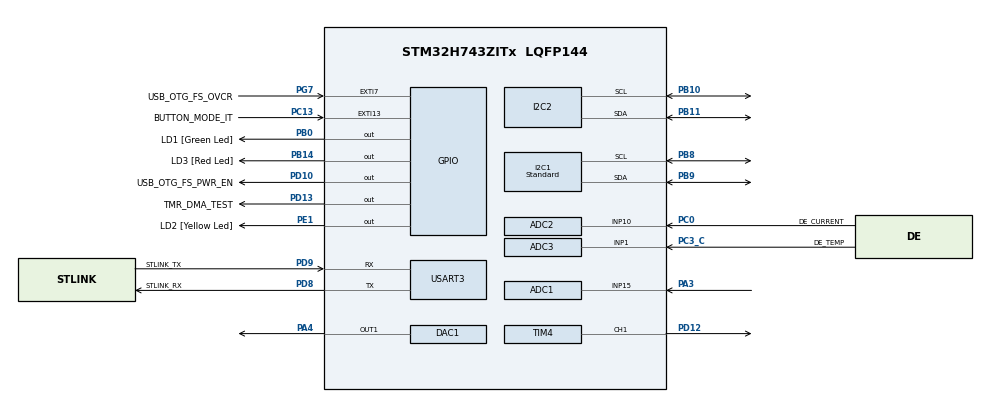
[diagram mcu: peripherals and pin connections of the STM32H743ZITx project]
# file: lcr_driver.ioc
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ADC1.Channel-0\#ChannelRegularConversion=ADC_CHANNEL_15
ADC1.ClockPrescaler=ADC_CLOCK_ASYNC_DIV1
ADC1.ContinuousConvMode=DISABLE
ADC1.ConversionDataManagement=ADC_CONVERSIONDATA_DMA_ONESHOT
ADC1.ExternalTrigConv=ADC_EXTERNALTRIG_T4_TRGO
ADC1.NbrOfConversion=1
ADC1.NbrOfConversionFlag=1
ADC1.OversamplingMode=ENABLE
ADC1.OversamplingStopReset=ADC_REGOVERSAMPLING_RESUMED_MODE
ADC1.Ratio=2
ADC1.RightBitShift=ADC_RIGHTBITSHIFT_1
ADC1.TriggeredMode=ADC_TRIGGEREDMODE_MULTI_TRIGGER
ADC1.master=1
ADC2.Channel-0\#ChannelRegularConversion=ADC_CHANNEL_10
ADC2.ContinuousConvMode=DISABLE
ADC2.ConversionDataManagement=ADC_CONVERSIONDATA_DMA_ONESHOT
ADC2.DiscontinuousConvMode=DISABLE
ADC2.ExternalTrigConv=ADC_EXTERNALTRIG_T4_TRGO
ADC2.NbrOfConversionFlag=1
ADC2.OffsetNumber-0\#ChannelRegularConversion=ADC_OFFSET_NONE
ADC2.OffsetSignedSaturation-0\#ChannelRegularConversion=DISABLE
ADC2.OversamplingMode=ENABLE
ADC2.OversamplingStopReset=ADC_REGOVERSAMPLING_RESUMED_MODE
ADC2.Rank-0\#ChannelRegularConversion=1
ADC2.Ratio=2
ADC2.Resolution=ADC_RESOLUTION_16B
ADC2.RightBitShift=ADC_RIGHTBITSHIFT_1
ADC2.SamplingTime-0\#ChannelRegularConversion=ADC_SAMPLETIME_1CYCLE_5
ADC2.TriggeredMode=ADC_TRIGGEREDMODE_MULTI_TRIGGER
ADC3.Channel-0\#ChannelRegularConversion=ADC_CHANNEL_1
ADC3.ContinuousConvMode=DISABLE
ADC3.ConversionDataManagement=ADC_CONVERSIONDATA_DMA_CIRCULAR
ADC3.ExternalTrigConv=ADC_EXTERNALTRIG_T4_TRGO
ADC3.NbrOfConversionFlag=1
ADC3.OffsetNumber-0\#ChannelRegularConversion=ADC_OFFSET_NONE
ADC3.OffsetSignedSaturation-0\#ChannelRegularConversion=DISABLE
ADC3.Rank-0\#ChannelRegularConversion=1
ADC3.SamplingTime-0\#ChannelRegularConversion=ADC_SAMPLETIME_1CYCLE_5
DAC1.DAC_Channel-DAC_OUT1=DAC_CHANNEL_1
DAC1.DAC_Trigger-DAC_OUT1=DAC_TRIGGER_T6_TRGO
Dma.ADC1.3.Direction=DMA_PERIPH_TO_MEMORY
Dma.ADC1.3.EventEnable=DISABLE
Dma.ADC1.3.FIFOMode=DMA_FIFOMODE_DISABLE
Dma.ADC1.3.Instance=DMA2_Stream0
Dma.ADC1.3.MemDataAlignment=DMA_MDATAALIGN_HALFWORD
Dma.ADC1.3.MemInc=DMA_MINC_ENABLE
Dma.ADC1.3.Mode=DMA_NORMAL
Dma.ADC1.3.PeriphDataAlignment=DMA_PDATAALIGN_HALFWORD
Dma.ADC1.3.PeriphInc=DMA_PINC_DISABLE
Dma.ADC1.3.Polarity=HAL_DMAMUX_REQ_GEN_RISING
Dma.ADC1.3.Priority=DMA_PRIORITY_LOW
Dma.ADC1.3.RequestNumber=1
Dma.ADC1.3.SignalID=NONE
Dma.ADC1.3.SyncEnable=DISABLE
Dma.ADC1.3.SyncPolarity=HAL_DMAMUX_SYNC_NO_EVENT
Dma.ADC1.3.SyncRequestNumber=1
Dma.ADC1.3.SyncSignalID=NONE
Dma.ADC2.1.Direction=DMA_PERIPH_TO_MEMORY
Dma.ADC2.1.EventEnable=DISABLE
Dma.ADC2.1.FIFOMode=DMA_FIFOMODE_DISABLE
Dma.ADC2.1.Instance=DMA2_Stream1
Dma.ADC2.1.MemDataAlignment=DMA_MDATAALIGN_HALFWORD
Dma.ADC2.1.MemInc=DMA_MINC_ENABLE
Dma.ADC2.1.Mode=DMA_NORMAL
Dma.ADC2.1.PeriphDataAlignment=DMA_PDATAALIGN_HALFWORD
Dma.ADC2.1.PeriphInc=DMA_PINC_DISABLE
Dma.ADC2.1.Polarity=HAL_DMAMUX_REQ_GEN_RISING
Dma.ADC2.1.Priority=DMA_PRIORITY_LOW
Dma.ADC2.1.RequestNumber=1
Dma.ADC2.1.SignalID=NONE
Dma.ADC2.1.SyncEnable=DISABLE
Dma.ADC2.1.SyncPolarity=HAL_DMAMUX_SYNC_NO_EVENT
Dma.ADC2.1.SyncRequestNumber=1
Dma.ADC2.1.SyncSignalID=NONE
Dma.ADC3.2.Direction=DMA_PERIPH_TO_MEMORY
Dma.ADC3.2.EventEnable=DISABLE
Dma.ADC3.2.FIFOMode=DMA_FIFOMODE_DISABLE
Dma.ADC3.2.Instance=DMA2_Stream2
Dma.ADC3.2.MemDataAlignment=DMA_MDATAALIGN_HALFWORD
Dma.ADC3.2.MemInc=DMA_MINC_ENABLE
Dma.ADC3.2.Mode=DMA_CIRCULAR
Dma.ADC3.2.PeriphDataAlignment=DMA_PDATAALIGN_HALFWORD
Dma.ADC3.2.PeriphInc=DMA_PINC_DISABLE
Dma.ADC3.2.Polarity=HAL_DMAMUX_REQ_GEN_RISING
Dma.ADC3.2.Priority=DMA_PRIORITY_LOW
Dma.ADC3.2.RequestNumber=1
Dma.ADC3.2.SignalID=NONE
Dma.ADC3.2.SyncEnable=DISABLE
Dma.ADC3.2.SyncPolarity=HAL_DMAMUX_SYNC_NO_EVENT
Dma.ADC3.2.SyncRequestNumber=1
Dma.ADC3.2.SyncSignalID=NONE
Dma.DAC1_CH1.0.Direction=DMA_MEMORY_TO_PERIPH
Dma.DAC1_CH1.0.EventEnable=DISABLE
Dma.DAC1_CH1.0.FIFOMode=DMA_FIFOMODE_DISABLE
Dma.DAC1_CH1.0.Instance=DMA1_Stream0
Dma.DAC1_CH1.0.MemDataAlignment=DMA_MDATAALIGN_HALFWORD
Dma.DAC1_CH1.0.MemInc=DMA_MINC_ENABLE
Dma.DAC1_CH1.0.Mode=DMA_CIRCULAR
Dma.DAC1_CH1.0.PeriphDataAlignment=DMA_PDATAALIGN_HALFWORD
Dma.DAC1_CH1.0.PeriphInc=DMA_PINC_DISABLE
Dma.DAC1_CH1.0.Polarity=HAL_DMAMUX_REQ_GEN_RISING
Dma.DAC1_CH1.0.Priority=DMA_PRIORITY_LOW
Dma.DAC1_CH1.0.RequestNumber=1
Dma.DAC1_CH1.0.SignalID=NONE
Dma.DAC1_CH1.0.SyncEnable=DISABLE
Dma.DAC1_CH1.0.SyncPolarity=HAL_DMAMUX_SYNC_NO_EVENT
Dma.DAC1_CH1.0.SyncRequestNumber=1
Dma.DAC1_CH1.0.SyncSignalID=NONE
Dma.Request0=DAC1_CH1
Dma.Request1=ADC2
Dma.Request2=ADC3
Dma.Request3=ADC1
FREERTOS.Tasks01=defaultTask,9,128,StartDefaultTask,Default,NULL,Dynamic,NULL,NULL;oledDisplay,17,512,Display_StartThread,As external,&hi2c1,Dynamic,NULL,NULL;analogOut,41,128,AnalogOut_StartThread,As external,&analog_out_params,Dynamic,NULL,NULL;mainThread,25,128,MainThread_StartThread,As external,&hi2c2,Dynamic,NULL,NULL;analogIn,42,2048,AnalogIn_StartThread,As external,&analog_in_params,Dynamic,NULL,NULL
FREERTOS.configUSE_NEWLIB_REENTRANT=1
I2C1.CustomTiming=Disabled
I2C1.I2C_Speed_Mode=I2C_Standard
I2C1.Timing=0x307075B1
I2C2.OwnAddress=0x60
I2C2.Timing=0x307075B1
Mcu.Family=STM32H7
Mcu.Name=STM32H743ZITx
Mcu.Package=LQFP144
NVIC.DMA1_Stream0_IRQn=true\:5\:0\:false\:false\:true\:true\:false\:true
NVIC.DMA2_Stream0_IRQn=true\:5\:0\:false\:false\:true\:false\:false\:true
NVIC.DMA2_Stream1_IRQn=true\:5\:0\:false\:false\:true\:true\:false\:true
NVIC.DMA2_Stream2_IRQn=true\:5\:0\:false\:false\:true\:true\:false\:true
NVIC.EXTI15_10_IRQn=true\:5\:0\:false\:false\:true\:true\:true\:true
NVIC.FLASH_IRQn=true\:5\:0\:false\:false\:true\:true\:true\:true
NVIC.I2C2_ER_IRQn=true\:5\:0\:false\:false\:true\:true\:true\:true
NVIC.I2C2_EV_IRQn=true\:5\:0\:false\:false\:true\:true\:true\:true
NVIC.PriorityGroup=NVIC_PRIORITYGROUP_4
NVIC.TIM7_IRQn=true\:15\:0\:false\:false\:true\:false\:false\:true
NVIC.TimeBase=TIM7_IRQn
NVIC.TimeBaseIP=TIM7
PA3.GPIO_Mode=GPIO_MODE_ANALOG
PA3.GPIO_PuPd=GPIO_NOPULL
PA3.Signal=ADCx_INP15
PA4.Signal=COMP_DAC11_group
PB0.GPIO_Label=LD1 [Green Led]
PB0.Signal=GPIO_Output
PB10.Mode=I2C
PB10.Signal=I2C2_SCL
PB11.Mode=I2C
PB11.Signal=I2C2_SDA
PB14.GPIO_Label=LD3 [Red Led]
PB14.Signal=GPIO_Output
PB8.Mode=I2C
PB8.Signal=I2C1_SCL
PB9.Mode=I2C
PB9.Signal=I2C1_SDA
PC0.GPIO_Label=DE_CURRENT
PC0.Signal=ADCx_INP10
PC13.GPIO_Label=BUTTON_MODE_IT
PC13.Signal=GPXTI13
PC14-OSC32_IN\ (OSC32_IN).Mode=LSE-External-Oscillator
PC14-OSC32_IN\ (OSC32_IN).Signal=RCC_OSC32_IN
PC15-OSC32_OUT\ (OSC32_OUT).Mode=LSE-External-Oscillator
PC15-OSC32_OUT\ (OSC32_OUT).Signal=RCC_OSC32_OUT
PC3_C.GPIO_Label=DE_TEMP
PC3_C.Mode=IN1-Single-Ended
PC3_C.Signal=ADC3_INP1
PD10.GPIO_Label=USB_OTG_FS_PWR_EN
PD10.Signal=GPIO_Output
PD12.Signal=S_TIM4_CH1
PD13.GPIO_Label=TMR_DMA_TEST
PD13.Signal=GPIO_Output
PD8.GPIO_Label=STLINK_RX
PD8.Mode=Asynchronous
PD8.Signal=USART3_TX
PD9.GPIO_Label=STLINK_TX
PD9.Mode=Asynchronous
PD9.Signal=USART3_RX
PE1.GPIO_Label=LD2 [Yellow Led]
PE1.Signal=GPIO_Output
PG7.GPIO_Label=USB_OTG_FS_OVCR
PG7.Signal=GPXTI7
PH0-OSC_IN\ (PH0).Mode=HSE-External-Clock-Source
PH0-OSC_IN\ (PH0).Signal=RCC_OSC_IN
ProjectManager.HeapSize=0x200
ProjectManager.StackSize=0x400
ProjectManager.TargetToolchain=STM32CubeIDE
RCC.ADCFreq_Value=75000000
RCC.APB1Freq_Value=120000000
RCC.APB2Freq_Value=120000000
RCC.APB3Freq_Value=120000000
RCC.APB4Freq_Value=120000000
RCC.CortexFreq_Value=480000000
RCC.D1PPRE=RCC_APB3_DIV2
RCC.D2PPRE1=RCC_APB1_DIV2
RCC.D2PPRE2=RCC_APB2_DIV2
RCC.D3PPRE=RCC_APB4_DIV2
RCC.DIVM1=4
RCC.DIVM2=4
RCC.DIVM3=4
RCC.DIVN1=60
RCC.DIVN2=9
RCC.DIVN3=10
RCC.HCLKFreq_Value=240000000
RCC.HPRE=RCC_HCLK_DIV2
RCC.PLL2FRACN=3072
RCC.PLL3FRACN=0
RCC.PLLFRACN=0
RCC.PWR_Regulator_Voltage_Scale=PWR_REGULATOR_VOLTAGE_SCALE0
RCC.SYSCLKFreq_VALUE=480000000
RCC.SYSCLKSource=RCC_SYSCLKSOURCE_PLLCLK
RCC.USBFreq_Value=480000000
SH.ADCx_INP10.0=ADC2_INP10,IN10-Single-Ended
SH.ADCx_INP15.0=ADC1_INP15,IN15-Single-Ended
SH.COMP_DAC11_group.0=DAC1_OUT1,DAC_OUT1
SH.S_TIM4_CH1.0=TIM4_CH1,Output Compare1 CH1
TIM4.AutoReloadPreload=TIM_AUTORELOAD_PRELOAD_ENABLE
TIM4.Channel-Output\ Compare1\ CH1=TIM_CHANNEL_1
TIM4.OCMode_1=TIM_OCMODE_TOGGLE
TIM4.Period=94-1
TIM4.TIM_MasterOutputTrigger=TIM_TRGO_UPDATE
TIM6.Period=240-1
TIM6.Prescaler=0
TIM6.TIM_MasterOutputTrigger=TIM_TRGO_UPDATE
USART3.VirtualMode-Asynchronous=VM_ASYNC
VP_FREERTOS_VS_CMSIS_V2.Mode=CMSIS_V2
VP_SYS_VS_tim7.Mode=TIM7
VP_TIM4_VS_ClockSourceINT.Mode=Internal
VP_TIM6_VS_ClockSourceINT.Mode=Enable_Timer
board=NUCLEO-H743ZI2

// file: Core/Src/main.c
/* USER CODE BEGIN Header */
/**
 ******************************************************************************
 * @file           : main.c
 * @brief          : Main program body
 ******************************************************************************
 * @attention
 *
 * <h2><center>&copy; Copyright (c) 2021 STMicroelectronics.
 * All rights reserved.</center></h2>
 *
 * This software component is licensed by ST under BSD 3-Clause license,
 * the "License"; You may not use this file except in compliance with the
 * License. You may obtain a copy of the License at:
 *                        opensource.org/licenses/BSD-3-Clause
 *
 ******************************************************************************
 */
/* USER CODE END Header */
#include "main.h"
#include "cmsis_os.h"

ADC_HandleTypeDef hadc1;
ADC_HandleTypeDef hadc2;
ADC_HandleTypeDef hadc3;
DMA_HandleTypeDef hdma_adc1;
DMA_HandleTypeDef hdma_adc2;
DMA_HandleTypeDef hdma_adc3;

DAC_HandleTypeDef hdac1;
DMA_HandleTypeDef hdma_dac1_ch1;

I2C_HandleTypeDef hi2c1;
I2C_HandleTypeDef hi2c2;

TIM_HandleTypeDef htim4;
TIM_HandleTypeDef htim6;

UART_HandleTypeDef huart3;

/* Definitions for defaultTask */
osThreadId_t defaultTaskHandle;
const osThreadAttr_t defaultTask_attributes = {
  .name = "defaultTask",
  .stack_size = 128 * 4,
  .priority = (osPriority_t) osPriorityLow1,
};
/* Definitions for oledDisplay */
osThreadId_t oledDisplayHandle;
const osThreadAttr_t oledDisplay_attributes = {
  .name = "oledDisplay",
  .stack_size = 512 * 4,
  .priority = (osPriority_t) osPriorityBelowNormal1,
};
/* Definitions for analogOut */
osThreadId_t analogOutHandle;
const osThreadAttr_t analogOut_attributes = {
  .name = "analogOut",
  .stack_size = 128 * 4,
  .priority = (osPriority_t) osPriorityHigh1,
};
/* Definitions for mainThread */
osThreadId_t mainThreadHandle;
const osThreadAttr_t mainThread_attributes = {
  .name = "mainThread",
  .stack_size = 128 * 4,
  .priority = (osPriority_t) osPriorityNormal1,
};
/* Definitions for analogIn */
osThreadId_t analogInHandle;
const osThreadAttr_t analogIn_attributes = {
  .name = "analogIn",
  .stack_size = 2048 * 4,
  .priority = (osPriority_t) osPriorityHigh2,
};
/* USER CODE BEGIN PV */

// these threads need multiple parameters, therefore we pass a reference to a struct
AnalogOut_Parameter_t analog_out_params = {&htim6, &hdac1, &hi2c1};
AnalogIn_Parameter_t analog_in_params = {&hadc1, &hadc2, &hadc3, &htim4};

/* USER CODE END PV */

void SystemClock_Config(void);
void PeriphCommonClock_Config(void);
static void MX_GPIO_Init(void);
static void MX_DMA_Init(void);
static void MX_TIM4_Init(void);
static void MX_TIM6_Init(void);
static void MX_USART3_UART_Init(void);
static void MX_DAC1_Init(void);
static void MX_ADC1_Init(void);
static void MX_ADC2_Init(void);
static void MX_ADC3_Init(void);
static void MX_I2C1_Init(void);
static void MX_I2C2_Init(void);
void StartDefaultTask(void *argument);
extern void Display_StartThread(void *argument);
extern void AnalogOut_StartThread(void *argument);
extern void MainThread_StartThread(void *argument);
extern void AnalogIn_StartThread(void *argument);

int main(void)
{

  /* MCU Configuration--------------------------------------------------------*/

  /* Reset of all peripherals, Initializes the Flash interface and the Systick. */
  HAL_Init();

  /* Configure the system clock */
  SystemClock_Config();

/* Configure the peripherals common clocks */
  PeriphCommonClock_Config();

  /* Initialize all configured peripherals */
  MX_GPIO_Init();
  MX_DMA_Init();
  MX_TIM4_Init();
  MX_TIM6_Init();
  MX_USART3_UART_Init();
  MX_DAC1_Init();
  MX_ADC1_Init();
  MX_ADC2_Init();
  MX_ADC3_Init();
  MX_I2C1_Init();
  MX_I2C2_Init();

  /* Init scheduler */
  osKernelInitialize();

  /* Create the thread(s) */
  /* creation of defaultTask */
  defaultTaskHandle = osThreadNew(StartDefaultTask, NULL, &defaultTask_attributes);

  /* creation of oledDisplay */
  oledDisplayHandle = osThreadNew(Display_StartThread, (void*) &hi2c1, &oledDisplay_attributes);

  /* creation of analogOut */
  analogOutHandle = osThreadNew(AnalogOut_StartThread, (void*) &analog_out_params, &analogOut_attributes);

  /* creation of mainThread */
  mainThreadHandle = osThreadNew(MainThread_StartThread, (void*) &hi2c2, &mainThread_attributes);

  /* creation of analogIn */
  analogInHandle = osThreadNew(AnalogIn_StartThread, (void*) &analog_in_params, &analogIn_attributes);

  /* Start scheduler */
  osKernelStart();

  /* We should never get here as control is now taken by the scheduler */
  /* Infinite loop */
  while (1) {

  }
}

void SystemClock_Config(void)
{
  RCC_OscInitTypeDef RCC_OscInitStruct = {0};
  RCC_ClkInitTypeDef RCC_ClkInitStruct = {0};

  /** Supply configuration update enable
  */
  HAL_PWREx_ConfigSupply(PWR_LDO_SUPPLY);
  /** Configure the main internal regulator output voltage
  */
  __HAL_PWR_VOLTAGESCALING_CONFIG(PWR_REGULATOR_VOLTAGE_SCALE0);

  while(!__HAL_PWR_GET_FLAG(PWR_FLAG_VOSRDY)) {}
  /** Macro to configure the PLL clock source
  */
  __HAL_RCC_PLL_PLLSOURCE_CONFIG(RCC_PLLSOURCE_HSI);
  /** Initializes the RCC Oscillators according to the specified parameters
  * in the RCC_OscInitTypeDef structure.
  */
  RCC_OscInitStruct.OscillatorType = RCC_OSCILLATORTYPE_HSI;
  RCC_OscInitStruct.HSIState = RCC_HSI_DIV1;
  RCC_OscInitStruct.HSICalibrationValue = RCC_HSICALIBRATION_DEFAULT;
  RCC_OscInitStruct.PLL.PLLState = RCC_PLL_ON;
  RCC_OscInitStruct.PLL.PLLSource = RCC_PLLSOURCE_HSI;
  RCC_OscInitStruct.PLL.PLLM = 4;
  RCC_OscInitStruct.PLL.PLLN = 60;
  RCC_OscInitStruct.PLL.PLLP = 2;
  RCC_OscInitStruct.PLL.PLLQ = 2;
  RCC_OscInitStruct.PLL.PLLR = 2;
  RCC_OscInitStruct.PLL.PLLRGE = RCC_PLL1VCIRANGE_3;
  RCC_OscInitStruct.PLL.PLLVCOSEL = RCC_PLL1VCOWIDE;
  RCC_OscInitStruct.PLL.PLLFRACN = 0;
  if (HAL_RCC_OscConfig(&RCC_OscInitStruct) != HAL_OK)
  {
    Error_Handler();
  }
  /** Initializes the CPU, AHB and APB buses clocks
  */
  RCC_ClkInitStruct.ClockType = RCC_CLOCKTYPE_HCLK|RCC_CLOCKTYPE_SYSCLK
                              |RCC_CLOCKTYPE_PCLK1|RCC_CLOCKTYPE_PCLK2
                              |RCC_CLOCKTYPE_D3PCLK1|RCC_CLOCKTYPE_D1PCLK1;
  RCC_ClkInitStruct.SYSCLKSource = RCC_SYSCLKSOURCE_PLLCLK;
  RCC_ClkInitStruct.SYSCLKDivider = RCC_SYSCLK_DIV1;
  RCC_ClkInitStruct.AHBCLKDivider = RCC_HCLK_DIV2;
  RCC_ClkInitStruct.APB3CLKDivider = RCC_APB3_DIV2;
  RCC_ClkInitStruct.APB1CLKDivider = RCC_APB1_DIV2;
  RCC_ClkInitStruct.APB2CLKDivider = RCC_APB2_DIV2;
  RCC_ClkInitStruct.APB4CLKDivider = RCC_APB4_DIV2;

  if (HAL_RCC_ClockConfig(&RCC_ClkInitStruct, FLASH_LATENCY_4) != HAL_OK)
  {
    Error_Handler();
  }
}

void PeriphCommonClock_Config(void)
{
  RCC_PeriphCLKInitTypeDef PeriphClkInitStruct = {0};

  /** Initializes the peripherals clock
  */
  PeriphClkInitStruct.PeriphClockSelection = RCC_PERIPHCLK_ADC;
  PeriphClkInitStruct.PLL2.PLL2M = 4;
  PeriphClkInitStruct.PLL2.PLL2N = 9;
  PeriphClkInitStruct.PLL2.PLL2P = 2;
  PeriphClkInitStruct.PLL2.PLL2Q = 2;
  PeriphClkInitStruct.PLL2.PLL2R = 2;
  PeriphClkInitStruct.PLL2.PLL2RGE = RCC_PLL2VCIRANGE_3;
  PeriphClkInitStruct.PLL2.PLL2VCOSEL = RCC_PLL2VCOMEDIUM;
  PeriphClkInitStruct.PLL2.PLL2FRACN = 3072;
  PeriphClkInitStruct.AdcClockSelection = RCC_ADCCLKSOURCE_PLL2;
  if (HAL_RCCEx_PeriphCLKConfig(&PeriphClkInitStruct) != HAL_OK)
  {
    Error_Handler();
  }
}

static void MX_ADC1_Init(void)
{

  ADC_MultiModeTypeDef multimode = {0};
  ADC_ChannelConfTypeDef sConfig = {0};

  /** Common config
  */
  hadc1.Instance = ADC1;
  hadc1.Init.ClockPrescaler = ADC_CLOCK_ASYNC_DIV1;
  hadc1.Init.Resolution = ADC_RESOLUTION_16B;
  hadc1.Init.ScanConvMode = ADC_SCAN_DISABLE;
  hadc1.Init.EOCSelection = ADC_EOC_SINGLE_CONV;
  hadc1.Init.LowPowerAutoWait = DISABLE;
  hadc1.Init.ContinuousConvMode = DISABLE;
  hadc1.Init.NbrOfConversion = 1;
  hadc1.Init.DiscontinuousConvMode = DISABLE;
  hadc1.Init.ExternalTrigConv = ADC_EXTERNALTRIG_T4_TRGO;
  hadc1.Init.ExternalTrigConvEdge = ADC_EXTERNALTRIGCONVEDGE_RISING;
  hadc1.Init.ConversionDataManagement = ADC_CONVERSIONDATA_DMA_ONESHOT;
  hadc1.Init.Overrun = ADC_OVR_DATA_PRESERVED;
  hadc1.Init.LeftBitShift = ADC_LEFTBITSHIFT_NONE;
  hadc1.Init.OversamplingMode = ENABLE;
  hadc1.Init.Oversampling.Ratio = 2;
  hadc1.Init.Oversampling.RightBitShift = ADC_RIGHTBITSHIFT_1;
  hadc1.Init.Oversampling.TriggeredMode = ADC_TRIGGEREDMODE_MULTI_TRIGGER;
  hadc1.Init.Oversampling.OversamplingStopReset = ADC_REGOVERSAMPLING_RESUMED_MODE;
  if (HAL_ADC_Init(&hadc1) != HAL_OK)
  {
    Error_Handler();
  }
  /** Configure the ADC multi-mode
  */
  multimode.Mode = ADC_MODE_INDEPENDENT;
  if (HAL_ADCEx_MultiModeConfigChannel(&hadc1, &multimode) != HAL_OK)
  {
    Error_Handler();
  }
  /** Configure Regular Channel
  */
  sConfig.Channel = ADC_CHANNEL_15;
  sConfig.Rank = ADC_REGULAR_RANK_1;
  sConfig.SamplingTime = ADC_SAMPLETIME_1CYCLE_5;
  sConfig.SingleDiff = ADC_SINGLE_ENDED;
  sConfig.OffsetNumber = ADC_OFFSET_NONE;
  sConfig.Offset = 0;
  sConfig.OffsetSignedSaturation = DISABLE;
  if (HAL_ADC_ConfigChannel(&hadc1, &sConfig) != HAL_OK)
  {
    Error_Handler();
  }

}

static void MX_ADC2_Init(void)
{

  ADC_ChannelConfTypeDef sConfig = {0};

  /** Common config
  */
  hadc2.Instance = ADC2;
  hadc2.Init.ClockPrescaler = ADC_CLOCK_ASYNC_DIV1;
  hadc2.Init.Resolution = ADC_RESOLUTION_16B;
  hadc2.Init.ScanConvMode = ADC_SCAN_DISABLE;
  hadc2.Init.EOCSelection = ADC_EOC_SINGLE_CONV;
  hadc2.Init.LowPowerAutoWait = DISABLE;
  hadc2.Init.ContinuousConvMode = DISABLE;
  hadc2.Init.NbrOfConversion = 1;
  hadc2.Init.DiscontinuousConvMode = DISABLE;
  hadc2.Init.ExternalTrigConv = ADC_EXTERNALTRIG_T4_TRGO;
  hadc2.Init.ExternalTrigConvEdge = ADC_EXTERNALTRIGCONVEDGE_RISING;
  hadc2.Init.ConversionDataManagement = ADC_CONVERSIONDATA_DMA_ONESHOT;
  hadc2.Init.Overrun = ADC_OVR_DATA_PRESERVED;
  hadc2.Init.LeftBitShift = ADC_LEFTBITSHIFT_NONE;
  hadc2.Init.OversamplingMode = ENABLE;
  hadc2.Init.Oversampling.Ratio = 2;
  hadc2.Init.Oversampling.RightBitShift = ADC_RIGHTBITSHIFT_1;
  hadc2.Init.Oversampling.TriggeredMode = ADC_TRIGGEREDMODE_MULTI_TRIGGER;
  hadc2.Init.Oversampling.OversamplingStopReset = ADC_REGOVERSAMPLING_RESUMED_MODE;
  if (HAL_ADC_Init(&hadc2) != HAL_OK)
  {
    Error_Handler();
  }
  /** Configure Regular Channel
  */
  sConfig.Channel = ADC_CHANNEL_10;
  sConfig.Rank = ADC_REGULAR_RANK_1;
  sConfig.SamplingTime = ADC_SAMPLETIME_1CYCLE_5;
  sConfig.SingleDiff = ADC_SINGLE_ENDED;
  sConfig.OffsetNumber = ADC_OFFSET_NONE;
  sConfig.Offset = 0;
  sConfig.OffsetSignedSaturation = DISABLE;
  if (HAL_ADC_ConfigChannel(&hadc2, &sConfig) != HAL_OK)
  {
    Error_Handler();
  }

}

static void MX_ADC3_Init(void)
{

  ADC_ChannelConfTypeDef sConfig = {0};

  /** Common config
  */
  hadc3.Instance = ADC3;
  hadc3.Init.ClockPrescaler = ADC_CLOCK_ASYNC_DIV1;
  hadc3.Init.Resolution = ADC_RESOLUTION_16B;
  hadc3.Init.ScanConvMode = ADC_SCAN_DISABLE;
  hadc3.Init.EOCSelection = ADC_EOC_SINGLE_CONV;
  hadc3.Init.LowPowerAutoWait = DISABLE;
  hadc3.Init.ContinuousConvMode = DISABLE;
  hadc3.Init.NbrOfConversion = 1;
  hadc3.Init.DiscontinuousConvMode = DISABLE;
  hadc3.Init.ExternalTrigConv = ADC_EXTERNALTRIG_T4_TRGO;
  hadc3.Init.ExternalTrigConvEdge = ADC_EXTERNALTRIGCONVEDGE_RISING;
  hadc3.Init.ConversionDataManagement = ADC_CONVERSIONDATA_DMA_CIRCULAR;
  hadc3.Init.Overrun = ADC_OVR_DATA_PRESERVED;
  hadc3.Init.LeftBitShift = ADC_LEFTBITSHIFT_NONE;
  hadc3.Init.OversamplingMode = DISABLE;
  if (HAL_ADC_Init(&hadc3) != HAL_OK)
  {
    Error_Handler();
  }
  /** Configure Regular Channel
  */
  sConfig.Channel = ADC_CHANNEL_1;
  sConfig.Rank = ADC_REGULAR_RANK_1;
  sConfig.SamplingTime = ADC_SAMPLETIME_1CYCLE_5;
  sConfig.SingleDiff = ADC_SINGLE_ENDED;
  sConfig.OffsetNumber = ADC_OFFSET_NONE;
  sConfig.Offset = 0;
  sConfig.OffsetSignedSaturation = DISABLE;
  if (HAL_ADC_ConfigChannel(&hadc3, &sConfig) != HAL_OK)
  {
    Error_Handler();
  }

}

static void MX_DAC1_Init(void)
{

  DAC_ChannelConfTypeDef sConfig = {0};

  /** DAC Initialization
  */
  hdac1.Instance = DAC1;
  if (HAL_DAC_Init(&hdac1) != HAL_OK)
  {
    Error_Handler();
  }
  /** DAC channel OUT1 config
  */
  sConfig.DAC_SampleAndHold = DAC_SAMPLEANDHOLD_DISABLE;
  sConfig.DAC_Trigger = DAC_TRIGGER_T6_TRGO;
  sConfig.DAC_OutputBuffer = DAC_OUTPUTBUFFER_ENABLE;
  sConfig.DAC_ConnectOnChipPeripheral = DAC_CHIPCONNECT_DISABLE;
  sConfig.DAC_UserTrimming = DAC_TRIMMING_FACTORY;
  if (HAL_DAC_ConfigChannel(&hdac1, &sConfig, DAC_CHANNEL_1) != HAL_OK)
  {
    Error_Handler();
  }

}

static void MX_I2C1_Init(void)
{

  hi2c1.Instance = I2C1;
  hi2c1.Init.Timing = 0x307075B1;
  hi2c1.Init.OwnAddress1 = 0;
  hi2c1.Init.AddressingMode = I2C_ADDRESSINGMODE_7BIT;
  hi2c1.Init.DualAddressMode = I2C_DUALADDRESS_DISABLE;
  hi2c1.Init.OwnAddress2 = 0;
  hi2c1.Init.OwnAddress2Masks = I2C_OA2_NOMASK;
  hi2c1.Init.GeneralCallMode = I2C_GENERALCALL_DISABLE;
  hi2c1.Init.NoStretchMode = I2C_NOSTRETCH_DISABLE;
  if (HAL_I2C_Init(&hi2c1) != HAL_OK)
  {
    Error_Handler();
  }
  /** Configure Analogue filter
  */
  if (HAL_I2CEx_ConfigAnalogFilter(&hi2c1, I2C_ANALOGFILTER_ENABLE) != HAL_OK)
  {
    Error_Handler();
  }
  /** Configure Digital filter
  */
  if (HAL_I2CEx_ConfigDigitalFilter(&hi2c1, 0) != HAL_OK)
  {
    Error_Handler();
  }

}

static void MX_I2C2_Init(void)
{

  hi2c2.Instance = I2C2;
  hi2c2.Init.Timing = 0x307075B1;
  hi2c2.Init.OwnAddress1 = 192;
  hi2c2.Init.AddressingMode = I2C_ADDRESSINGMODE_7BIT;
  hi2c2.Init.DualAddressMode = I2C_DUALADDRESS_DISABLE;
  hi2c2.Init.OwnAddress2 = 0;
  hi2c2.Init.OwnAddress2Masks = I2C_OA2_NOMASK;
  hi2c2.Init.GeneralCallMode = I2C_GENERALCALL_DISABLE;
  hi2c2.Init.NoStretchMode = I2C_NOSTRETCH_DISABLE;
  if (HAL_I2C_Init(&hi2c2) != HAL_OK)
  {
    Error_Handler();
  }
  /** Configure Analogue filter
  */
  if (HAL_I2CEx_ConfigAnalogFilter(&hi2c2, I2C_ANALOGFILTER_ENABLE) != HAL_OK)
  {
    Error_Handler();
  }
  /** Configure Digital filter
  */
  if (HAL_I2CEx_ConfigDigitalFilter(&hi2c2, 0) != HAL_OK)
  {
    Error_Handler();
  }

}

static void MX_TIM4_Init(void)
{

  TIM_ClockConfigTypeDef sClockSourceConfig = {0};
  TIM_MasterConfigTypeDef sMasterConfig = {0};
  TIM_OC_InitTypeDef sConfigOC = {0};

  htim4.Instance = TIM4;
  htim4.Init.Prescaler = 0;
  htim4.Init.CounterMode = TIM_COUNTERMODE_UP;
  htim4.Init.Period = 94-1;
  htim4.Init.ClockDivision = TIM_CLOCKDIVISION_DIV1;
  htim4.Init.AutoReloadPreload = TIM_AUTORELOAD_PRELOAD_ENABLE;
  if (HAL_TIM_Base_Init(&htim4) != HAL_OK)
  {
    Error_Handler();
  }
  sClockSourceConfig.ClockSource = TIM_CLOCKSOURCE_INTERNAL;
  if (HAL_TIM_ConfigClockSource(&htim4, &sClockSourceConfig) != HAL_OK)
  {
    Error_Handler();
  }
  if (HAL_TIM_OC_Init(&htim4) != HAL_OK)
  {
    Error_Handler();
  }
  sMasterConfig.MasterOutputTrigger = TIM_TRGO_UPDATE;
  sMasterConfig.MasterSlaveMode = TIM_MASTERSLAVEMODE_DISABLE;
  if (HAL_TIMEx_MasterConfigSynchronization(&htim4, &sMasterConfig) != HAL_OK)
  {
    Error_Handler();
  }
  sConfigOC.OCMode = TIM_OCMODE_TOGGLE;
  sConfigOC.Pulse = 0;
  sConfigOC.OCPolarity = TIM_OCPOLARITY_HIGH;
  sConfigOC.OCFastMode = TIM_OCFAST_DISABLE;
  if (HAL_TIM_OC_ConfigChannel(&htim4, &sConfigOC, TIM_CHANNEL_1) != HAL_OK)
  {
    Error_Handler();
  }
  HAL_TIM_MspPostInit(&htim4);

}

static void MX_TIM6_Init(void)
{

  TIM_MasterConfigTypeDef sMasterConfig = {0};

  htim6.Instance = TIM6;
  htim6.Init.Prescaler = 0;
  htim6.Init.CounterMode = TIM_COUNTERMODE_UP;
  htim6.Init.Period = 240-1;
  htim6.Init.AutoReloadPreload = TIM_AUTORELOAD_PRELOAD_DISABLE;
  if (HAL_TIM_Base_Init(&htim6) != HAL_OK)
  {
    Error_Handler();
  }
  sMasterConfig.MasterOutputTrigger = TIM_TRGO_UPDATE;
  sMasterConfig.MasterSlaveMode = TIM_MASTERSLAVEMODE_DISABLE;
  if (HAL_TIMEx_MasterConfigSynchronization(&htim6, &sMasterConfig) != HAL_OK)
  {
    Error_Handler();
  }

}

static void MX_USART3_UART_Init(void)
{

  huart3.Instance = USART3;
  huart3.Init.BaudRate = 115200;
  huart3.Init.WordLength = UART_WORDLENGTH_8B;
  huart3.Init.StopBits = UART_STOPBITS_1;
  huart3.Init.Parity = UART_PARITY_NONE;
  huart3.Init.Mode = UART_MODE_TX_RX;
  huart3.Init.HwFlowCtl = UART_HWCONTROL_NONE;
  huart3.Init.OverSampling = UART_OVERSAMPLING_16;
  huart3.Init.OneBitSampling = UART_ONE_BIT_SAMPLE_DISABLE;
  huart3.Init.ClockPrescaler = UART_PRESCALER_DIV1;
  huart3.AdvancedInit.AdvFeatureInit = UART_ADVFEATURE_NO_INIT;
  if (HAL_UART_Init(&huart3) != HAL_OK)
  {
    Error_Handler();
  }
  if (HAL_UARTEx_SetTxFifoThreshold(&huart3, UART_TXFIFO_THRESHOLD_1_8) != HAL_OK)
  {
    Error_Handler();
  }
  if (HAL_UARTEx_SetRxFifoThreshold(&huart3, UART_RXFIFO_THRESHOLD_1_8) != HAL_OK)
  {
    Error_Handler();
  }
  if (HAL_UARTEx_DisableFifoMode(&huart3) != HAL_OK)
  {
    Error_Handler();
  }

}

static void MX_DMA_Init(void)
{

  /* DMA controller clock enable */
  __HAL_RCC_DMA1_CLK_ENABLE();
  __HAL_RCC_DMA2_CLK_ENABLE();

  /* DMA interrupt init */
  /* DMA1_Stream0_IRQn interrupt configuration */
  HAL_NVIC_SetPriority(DMA1_Stream0_IRQn, 5, 0);
  HAL_NVIC_EnableIRQ(DMA1_Stream0_IRQn);
  /* DMA2_Stream0_IRQn interrupt configuration */
  HAL_NVIC_SetPriority(DMA2_Stream0_IRQn, 5, 0);
  HAL_NVIC_EnableIRQ(DMA2_Stream0_IRQn);
  /* DMA2_Stream1_IRQn interrupt configuration */
  HAL_NVIC_SetPriority(DMA2_Stream1_IRQn, 5, 0);
  HAL_NVIC_EnableIRQ(DMA2_Stream1_IRQn);
  /* DMA2_Stream2_IRQn interrupt configuration */
  HAL_NVIC_SetPriority(DMA2_Stream2_IRQn, 5, 0);
  HAL_NVIC_EnableIRQ(DMA2_Stream2_IRQn);

}

static void MX_GPIO_Init(void)
{
  GPIO_InitTypeDef GPIO_InitStruct = {0};

  /* GPIO Ports Clock Enable */
  __HAL_RCC_GPIOC_CLK_ENABLE();
  __HAL_RCC_GPIOH_CLK_ENABLE();
  __HAL_RCC_GPIOA_CLK_ENABLE();
  __HAL_RCC_GPIOB_CLK_ENABLE();
  __HAL_RCC_GPIOD_CLK_ENABLE();
  __HAL_RCC_GPIOG_CLK_ENABLE();
  __HAL_RCC_GPIOE_CLK_ENABLE();

  /*Configure GPIO pin Output Level */
  HAL_GPIO_WritePin(GPIOB, LD1_Pin|LD3_Pin, GPIO_PIN_RESET);

  /*Configure GPIO pin Output Level */
  HAL_GPIO_WritePin(GPIOD, USB_OTG_FS_PWR_EN_Pin|TMR_DMA_TEST_Pin, GPIO_PIN_RESET);

  /*Configure GPIO pin Output Level */
  HAL_GPIO_WritePin(LD2_GPIO_Port, LD2_Pin, GPIO_PIN_RESET);

  /*Configure GPIO pin : BUTTON_MODE_IT_Pin */
  GPIO_InitStruct.Pin = BUTTON_MODE_IT_Pin;
  GPIO_InitStruct.Mode = GPIO_MODE_IT_RISING;
  GPIO_InitStruct.Pull = GPIO_NOPULL;
  HAL_GPIO_Init(BUTTON_MODE_IT_GPIO_Port, &GPIO_InitStruct);

  /*Configure GPIO pins : LD1_Pin LD3_Pin */
  GPIO_InitStruct.Pin = LD1_Pin|LD3_Pin;
  GPIO_InitStruct.Mode = GPIO_MODE_OUTPUT_PP;
  GPIO_InitStruct.Pull = GPIO_NOPULL;
  GPIO_InitStruct.Speed = GPIO_SPEED_FREQ_LOW;
  HAL_GPIO_Init(GPIOB, &GPIO_InitStruct);

  /*Configure GPIO pins : USB_OTG_FS_PWR_EN_Pin TMR_DMA_TEST_Pin */
  GPIO_InitStruct.Pin = USB_OTG_FS_PWR_EN_Pin|TMR_DMA_TEST_Pin;
  GPIO_InitStruct.Mode = GPIO_MODE_OUTPUT_PP;
  GPIO_InitStruct.Pull = GPIO_NOPULL;
  GPIO_InitStruct.Speed = GPIO_SPEED_FREQ_LOW;
  HAL_GPIO_Init(GPIOD, &GPIO_InitStruct);

  /*Configure GPIO pin : USB_OTG_FS_OVCR_Pin */
  GPIO_InitStruct.Pin = USB_OTG_FS_OVCR_Pin;
  GPIO_InitStruct.Mode = GPIO_MODE_IT_RISING;
  GPIO_InitStruct.Pull = GPIO_NOPULL;
  HAL_GPIO_Init(USB_OTG_FS_OVCR_GPIO_Port, &GPIO_InitStruct);

  /*Configure GPIO pin : LD2_Pin */
  GPIO_InitStruct.Pin = LD2_Pin;
  GPIO_InitStruct.Mode = GPIO_MODE_OUTPUT_PP;
  GPIO_InitStruct.Pull = GPIO_NOPULL;
  GPIO_InitStruct.Speed = GPIO_SPEED_FREQ_LOW;
  HAL_GPIO_Init(LD2_GPIO_Port, &GPIO_InitStruct);

  /* EXTI interrupt init*/
  HAL_NVIC_SetPriority(EXTI15_10_IRQn, 5, 0);
  HAL_NVIC_EnableIRQ(EXTI15_10_IRQn);

}

void StartDefaultTask(void *argument)
{
  for(;;)
  {
    osDelay(1);
  }
}

void HAL_TIM_PeriodElapsedCallback(TIM_HandleTypeDef *htim)
{
  if (htim->Instance == TIM7) {
    HAL_IncTick();
  }
}

void Error_Handler(void)
{
  __disable_irq();
  while (1) {
  }
}

/************************ (C) COPYRIGHT STMicroelectronics *****END OF FILE****/
